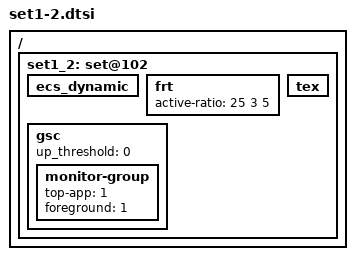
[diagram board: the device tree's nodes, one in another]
/ {
	/* power-scenario mode - app boost */
	set1_2: set@102 {

		ecs_dynamic { };

		frt {	   			/* LIT MED BIG */
			active-ratio 		= < 25   3   5>;
		};

		tex { };

		gsc {
			up_threshold = <0>;

			monitor-group {
				top-app = <1>;
				foreground = <1>;
			};
		};
	};
};
